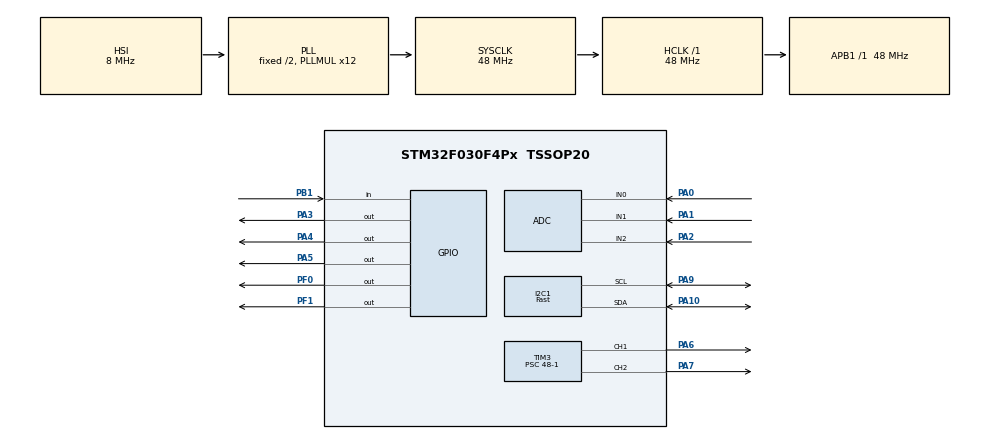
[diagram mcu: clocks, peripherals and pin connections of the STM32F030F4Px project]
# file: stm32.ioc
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ADC.ContinuousConvMode=DISABLE
ADC.DMAContinuousRequests=ENABLE
ADC.EOCSelection=ADC_EOC_SEQ_CONV
ADC.ExternalTrigConv=ADC_EXTERNALTRIGCONV_T1_CC4
ADC.ExternalTrigConvEdge=ADC_EXTERNALTRIGCONVEDGE_FALLING
ADC.SamplingTime=ADC_SAMPLETIME_71CYCLES_5
Dma.ADC.0.Direction=DMA_PERIPH_TO_MEMORY
Dma.ADC.0.Instance=DMA1_Channel1
Dma.ADC.0.MemDataAlignment=DMA_MDATAALIGN_HALFWORD
Dma.ADC.0.MemInc=DMA_MINC_ENABLE
Dma.ADC.0.Mode=DMA_CIRCULAR
Dma.ADC.0.PeriphDataAlignment=DMA_PDATAALIGN_HALFWORD
Dma.ADC.0.PeriphInc=DMA_PINC_DISABLE
Dma.ADC.0.Priority=DMA_PRIORITY_HIGH
Dma.Request0=ADC
I2C1.Analog_Filter=I2C_ANALOGFILTER_ENABLE
I2C1.I2C_Fall_Time=300
I2C1.I2C_Rise_Time=300
I2C1.I2C_Speed_Mode=I2C_Fast
I2C1.OwnAddress=0x58
I2C1.Timing=0x00300208
Mcu.Family=STM32F0
Mcu.Name=STM32F030F4Px
Mcu.Package=TSSOP20
NVIC.DMA1_Channel1_IRQn=true\:1\:0\:true\:false\:true\:false\:true
NVIC.I2C1_IRQn=true\:0\:0\:false\:false\:true\:true\:true
NVIC.TIM14_IRQn=true\:3\:0\:true\:false\:true\:false\:true
NVIC.TimeBase=TIM14_IRQn
NVIC.TimeBaseIP=TIM14
PA0.Mode=IN0
PA0.Signal=ADC_IN0
PA1.Mode=IN1
PA1.Signal=ADC_IN1
PA10.Mode=I2C
PA10.Signal=I2C1_SDA
PA13.Mode=Serial_Wire
PA13.Signal=SYS_SWDIO
PA14.Mode=Serial_Wire
PA14.Signal=SYS_SWCLK
PA2.Mode=IN2
PA2.Signal=ADC_IN2
PA3.GPIO_Speed=GPIO_SPEED_FREQ_MEDIUM
PA3.Signal=GPIO_Output
PA4.GPIO_Speed=GPIO_SPEED_FREQ_MEDIUM
PA4.Signal=GPIO_Output
PA5.Signal=GPIO_Output
PA6.Signal=S_TIM3_CH1
PA7.Signal=S_TIM3_CH2
PA9.Mode=I2C
PA9.Signal=I2C1_SCL
PB1.Signal=GPIO_Input
PF0-OSC_IN.GPIO_Speed=GPIO_SPEED_FREQ_MEDIUM
PF0-OSC_IN.Signal=GPIO_Output
PF1-OSC_OUT.GPIO_Speed=GPIO_SPEED_FREQ_MEDIUM
PF1-OSC_OUT.Signal=GPIO_Output
ProjectManager.HeapSize=0x0
ProjectManager.StackSize=0x400
ProjectManager.TargetToolchain=MDK-ARM V5
RCC.AHBFreq_Value=48000000
RCC.APB1Freq_Value=48000000
RCC.APB1TimFreq_Value=48000000
RCC.HCLKFreq_Value=48000000
RCC.PLLMUL=RCC_PLL_MUL12
RCC.SYSCLKFreq_VALUE=48000000
RCC.SYSCLKSource=RCC_SYSCLKSOURCE_PLLCLK
SH.S_TIM3_CH1.0=TIM3_CH1,PWM Generation1 CH1
SH.S_TIM3_CH2.0=TIM3_CH2,PWM Generation2 CH2
TIM1.AutoReloadPreload=TIM_AUTORELOAD_PRELOAD_ENABLE
TIM1.Channel-PWM\ Generation4\ No\ Output=TIM_CHANNEL_4
TIM1.Period=1000-1
TIM1.Prescaler=48-1
TIM1.Pulse-PWM\ Generation4\ No\ Output=1
TIM1.TIM_MasterOutputTrigger=TIM_TRGO_OC4REF
TIM3.AutoReloadPreload=TIM_AUTORELOAD_PRELOAD_ENABLE
TIM3.Channel-PWM\ Generation1\ CH1=TIM_CHANNEL_1
TIM3.Channel-PWM\ Generation2\ CH2=TIM_CHANNEL_2
TIM3.Period=1000
TIM3.Prescaler=48-1
VP_SYS_VS_tim14.Mode=TIM14
VP_TIM1_VS_no_output4.Mode=PWM Generation4 No Output
board=custom

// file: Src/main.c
/* USER CODE BEGIN Header */
/**
  ******************************************************************************
  * @file           : main.c
  * @brief          : Main program body
  ******************************************************************************
  * @attention
  *
  * <h2><center>&copy; Copyright (c) 2019 STMicroelectronics.
  * All rights reserved.</center></h2>
  *
  * This software component is licensed by ST under BSD 3-Clause license,
  * the "License"; You may not use this file except in compliance with the
  * License. You may obtain a copy of the License at:
  *                        opensource.org/licenses/BSD-3-Clause
  *
  ******************************************************************************
  */
/* USER CODE END Header */

#include "main.h"
#include "user.h"
volatile uint16_t ADC_Raw[3];

ADC_HandleTypeDef hadc;
DMA_HandleTypeDef hdma_adc;

I2C_HandleTypeDef hi2c1;

TIM_HandleTypeDef htim1;
TIM_HandleTypeDef htim3;

void SystemClock_Config(void);
static void MX_GPIO_Init(void);
static void MX_DMA_Init(void);
static void MX_ADC_Init(void);
static void MX_I2C1_Init(void);
static void MX_TIM3_Init(void);
static void MX_TIM1_Init(void);

int main(void)
{

	/* MCU Configuration--------------------------------------------------------*/

	/* Reset of all peripherals, Initializes the Flash interface and the Systick. */
	HAL_Init();

	/* Configure the system clock */
	SystemClock_Config();

	/* Initialize all configured peripherals */
	MX_GPIO_Init();
	MX_DMA_Init();
	MX_ADC_Init();
	MX_I2C1_Init();
	MX_TIM3_Init();
	MX_TIM1_Init();
	/* USER CODE BEGIN 2 */
	__HAL_TIM_SET_AUTORELOAD(&htim3, 1000);
	HAL_TIM_PWM_Start(&htim3, TIM_CHANNEL_1);
	HAL_TIM_PWM_Start(&htim3, TIM_CHANNEL_2);

	// 5k Hz
	__HAL_TIM_SET_AUTORELOAD(&htim1, 200 - 1);

	__HAL_TIM_SET_COMPARE(&htim1, TIM_CHANNEL_4, 1);
	HAL_TIM_OC_Start_IT(&htim1, TIM_CHANNEL_4);
	HAL_ADC_Start_DMA(&hadc, (uint32_t *)ADC_Raw, 3);

	/* USER CODE END 2 */

	/* Infinite loop */
	while (1)
	{
		user_loop();
	}
}

void SystemClock_Config(void)
{
	RCC_OscInitTypeDef RCC_OscInitStruct = {0};
	RCC_ClkInitTypeDef RCC_ClkInitStruct = {0};
	RCC_PeriphCLKInitTypeDef PeriphClkInit = {0};

	/** Initializes the CPU, AHB and APB busses clocks
  */
	RCC_OscInitStruct.OscillatorType = RCC_OSCILLATORTYPE_HSI | RCC_OSCILLATORTYPE_HSI14;
	RCC_OscInitStruct.HSIState = RCC_HSI_ON;
	RCC_OscInitStruct.HSI14State = RCC_HSI14_ON;
	RCC_OscInitStruct.HSICalibrationValue = RCC_HSICALIBRATION_DEFAULT;
	RCC_OscInitStruct.HSI14CalibrationValue = 16;
	RCC_OscInitStruct.PLL.PLLState = RCC_PLL_ON;
	RCC_OscInitStruct.PLL.PLLSource = RCC_PLLSOURCE_HSI;
	RCC_OscInitStruct.PLL.PLLMUL = RCC_PLL_MUL12;
	RCC_OscInitStruct.PLL.PREDIV = RCC_PREDIV_DIV1;
	if (HAL_RCC_OscConfig(&RCC_OscInitStruct) != HAL_OK)
	{
		Error_Handler();
	}
	/** Initializes the CPU, AHB and APB busses clocks
  */
	RCC_ClkInitStruct.ClockType = RCC_CLOCKTYPE_HCLK | RCC_CLOCKTYPE_SYSCLK | RCC_CLOCKTYPE_PCLK1;
	RCC_ClkInitStruct.SYSCLKSource = RCC_SYSCLKSOURCE_PLLCLK;
	RCC_ClkInitStruct.AHBCLKDivider = RCC_SYSCLK_DIV1;
	RCC_ClkInitStruct.APB1CLKDivider = RCC_HCLK_DIV1;

	if (HAL_RCC_ClockConfig(&RCC_ClkInitStruct, FLASH_LATENCY_1) != HAL_OK)
	{
		Error_Handler();
	}
	PeriphClkInit.PeriphClockSelection = RCC_PERIPHCLK_I2C1;
	PeriphClkInit.I2c1ClockSelection = RCC_I2C1CLKSOURCE_HSI;
	if (HAL_RCCEx_PeriphCLKConfig(&PeriphClkInit) != HAL_OK)
	{
		Error_Handler();
	}
}

static void MX_ADC_Init(void)
{

	ADC_ChannelConfTypeDef sConfig = {0};

	/** Configure the global features of the ADC (Clock, Resolution, Data Alignment and number of conversion)
  */
	hadc.Instance = ADC1;
	hadc.Init.ClockPrescaler = ADC_CLOCK_ASYNC_DIV1;
	hadc.Init.Resolution = ADC_RESOLUTION_12B;
	hadc.Init.DataAlign = ADC_DATAALIGN_RIGHT;
	hadc.Init.ScanConvMode = ADC_SCAN_DIRECTION_FORWARD;
	hadc.Init.EOCSelection = ADC_EOC_SEQ_CONV;
	hadc.Init.LowPowerAutoWait = DISABLE;
	hadc.Init.LowPowerAutoPowerOff = DISABLE;
	hadc.Init.ContinuousConvMode = DISABLE;
	hadc.Init.DiscontinuousConvMode = DISABLE;
	hadc.Init.ExternalTrigConv = ADC_EXTERNALTRIGCONV_T1_CC4;
	hadc.Init.ExternalTrigConvEdge = ADC_EXTERNALTRIGCONVEDGE_FALLING;
	hadc.Init.DMAContinuousRequests = ENABLE;
	hadc.Init.Overrun = ADC_OVR_DATA_PRESERVED;
	if (HAL_ADC_Init(&hadc) != HAL_OK)
	{
		Error_Handler();
	}
	/** Configure for the selected ADC regular channel to be converted.
  */
	sConfig.Channel = ADC_CHANNEL_0;
	sConfig.Rank = ADC_RANK_CHANNEL_NUMBER;
	sConfig.SamplingTime = ADC_SAMPLETIME_71CYCLES_5;
	if (HAL_ADC_ConfigChannel(&hadc, &sConfig) != HAL_OK)
	{
		Error_Handler();
	}
	/** Configure for the selected ADC regular channel to be converted.
  */
	sConfig.Channel = ADC_CHANNEL_1;
	if (HAL_ADC_ConfigChannel(&hadc, &sConfig) != HAL_OK)
	{
		Error_Handler();
	}
	/** Configure for the selected ADC regular channel to be converted.
  */
	sConfig.Channel = ADC_CHANNEL_2;
	if (HAL_ADC_ConfigChannel(&hadc, &sConfig) != HAL_OK)
	{
		Error_Handler();
	}
}

static void MX_I2C1_Init(void)
{

	hi2c1.Instance = I2C1;
	hi2c1.Init.Timing = 0x00300208;
	hi2c1.Init.OwnAddress1 = 176;
	hi2c1.Init.AddressingMode = I2C_ADDRESSINGMODE_7BIT;
	hi2c1.Init.DualAddressMode = I2C_DUALADDRESS_DISABLE;
	hi2c1.Init.OwnAddress2 = 0;
	hi2c1.Init.OwnAddress2Masks = I2C_OA2_NOMASK;
	hi2c1.Init.GeneralCallMode = I2C_GENERALCALL_DISABLE;
	hi2c1.Init.NoStretchMode = I2C_NOSTRETCH_DISABLE;
	if (HAL_I2C_Init(&hi2c1) != HAL_OK)
	{
		Error_Handler();
	}
	/** Configure Analogue filter
  */
	if (HAL_I2CEx_ConfigAnalogFilter(&hi2c1, I2C_ANALOGFILTER_ENABLE) != HAL_OK)
	{
		Error_Handler();
	}
	/** Configure Digital filter
  */
	if (HAL_I2CEx_ConfigDigitalFilter(&hi2c1, 0) != HAL_OK)
	{
		Error_Handler();
	}
}

static void MX_TIM1_Init(void)
{

	TIM_MasterConfigTypeDef sMasterConfig = {0};
	TIM_OC_InitTypeDef sConfigOC = {0};
	TIM_BreakDeadTimeConfigTypeDef sBreakDeadTimeConfig = {0};

	htim1.Instance = TIM1;
	htim1.Init.Prescaler = 48 - 1;
	htim1.Init.CounterMode = TIM_COUNTERMODE_UP;
	htim1.Init.Period = 100 - 1;
	htim1.Init.ClockDivision = TIM_CLOCKDIVISION_DIV1;
	htim1.Init.RepetitionCounter = 0;
	htim1.Init.AutoReloadPreload = TIM_AUTORELOAD_PRELOAD_ENABLE;
	if (HAL_TIM_PWM_Init(&htim1) != HAL_OK)
	{
		Error_Handler();
	}
	sMasterConfig.MasterOutputTrigger = TIM_TRGO_OC4REF;
	sMasterConfig.MasterSlaveMode = TIM_MASTERSLAVEMODE_DISABLE;
	if (HAL_TIMEx_MasterConfigSynchronization(&htim1, &sMasterConfig) != HAL_OK)
	{
		Error_Handler();
	}
	sConfigOC.OCMode = TIM_OCMODE_PWM1;
	sConfigOC.Pulse = 1;
	sConfigOC.OCPolarity = TIM_OCPOLARITY_HIGH;
	sConfigOC.OCFastMode = TIM_OCFAST_DISABLE;
	sConfigOC.OCIdleState = TIM_OCIDLESTATE_RESET;
	sConfigOC.OCNIdleState = TIM_OCNIDLESTATE_RESET;
	if (HAL_TIM_PWM_ConfigChannel(&htim1, &sConfigOC, TIM_CHANNEL_4) != HAL_OK)
	{
		Error_Handler();
	}
	sBreakDeadTimeConfig.OffStateRunMode = TIM_OSSR_DISABLE;
	sBreakDeadTimeConfig.OffStateIDLEMode = TIM_OSSI_DISABLE;
	sBreakDeadTimeConfig.LockLevel = TIM_LOCKLEVEL_OFF;
	sBreakDeadTimeConfig.DeadTime = 0;
	sBreakDeadTimeConfig.BreakState = TIM_BREAK_DISABLE;
	sBreakDeadTimeConfig.BreakPolarity = TIM_BREAKPOLARITY_HIGH;
	sBreakDeadTimeConfig.AutomaticOutput = TIM_AUTOMATICOUTPUT_DISABLE;
	if (HAL_TIMEx_ConfigBreakDeadTime(&htim1, &sBreakDeadTimeConfig) != HAL_OK)
	{
		Error_Handler();
	}
}

static void MX_TIM3_Init(void)
{

	TIM_MasterConfigTypeDef sMasterConfig = {0};
	TIM_OC_InitTypeDef sConfigOC = {0};

	htim3.Instance = TIM3;
	htim3.Init.Prescaler = 3 - 1;
	htim3.Init.CounterMode = TIM_COUNTERMODE_UP;
	htim3.Init.Period = 1000;
	htim3.Init.ClockDivision = TIM_CLOCKDIVISION_DIV1;
	htim3.Init.AutoReloadPreload = TIM_AUTORELOAD_PRELOAD_ENABLE;
	if (HAL_TIM_PWM_Init(&htim3) != HAL_OK)
	{
		Error_Handler();
	}
	sMasterConfig.MasterOutputTrigger = TIM_TRGO_RESET;
	sMasterConfig.MasterSlaveMode = TIM_MASTERSLAVEMODE_DISABLE;
	if (HAL_TIMEx_MasterConfigSynchronization(&htim3, &sMasterConfig) != HAL_OK)
	{
		Error_Handler();
	}
	sConfigOC.OCMode = TIM_OCMODE_PWM1;
	sConfigOC.Pulse = 0;
	sConfigOC.OCPolarity = TIM_OCPOLARITY_HIGH;
	sConfigOC.OCFastMode = TIM_OCFAST_DISABLE;
	if (HAL_TIM_PWM_ConfigChannel(&htim3, &sConfigOC, TIM_CHANNEL_1) != HAL_OK)
	{
		Error_Handler();
	}
	if (HAL_TIM_PWM_ConfigChannel(&htim3, &sConfigOC, TIM_CHANNEL_2) != HAL_OK)
	{
		Error_Handler();
	}
	HAL_TIM_MspPostInit(&htim3);
}

static void MX_DMA_Init(void)
{
	/* DMA controller clock enable */
	__HAL_RCC_DMA1_CLK_ENABLE();

	/* DMA interrupt init */
	/* DMA1_Channel1_IRQn interrupt configuration */
	HAL_NVIC_SetPriority(DMA1_Channel1_IRQn, 1, 0);
	HAL_NVIC_EnableIRQ(DMA1_Channel1_IRQn);
}

static void MX_GPIO_Init(void)
{
	GPIO_InitTypeDef GPIO_InitStruct = {0};

	/* GPIO Ports Clock Enable */
	__HAL_RCC_GPIOF_CLK_ENABLE();
	__HAL_RCC_GPIOA_CLK_ENABLE();
	__HAL_RCC_GPIOB_CLK_ENABLE();

	/*Configure GPIO pin Output Level */
	HAL_GPIO_WritePin(GPIOF, GPIO_PIN_0 | GPIO_PIN_1, GPIO_PIN_RESET);

	/*Configure GPIO pin Output Level */
	HAL_GPIO_WritePin(GPIOA, GPIO_PIN_3 | GPIO_PIN_4 | GPIO_PIN_5, GPIO_PIN_RESET);

	/*Configure GPIO pins : PF0 PF1 */
	GPIO_InitStruct.Pin = GPIO_PIN_0 | GPIO_PIN_1;
	GPIO_InitStruct.Mode = GPIO_MODE_OUTPUT_PP;
	GPIO_InitStruct.Pull = GPIO_NOPULL;
	GPIO_InitStruct.Speed = GPIO_SPEED_FREQ_MEDIUM;
	HAL_GPIO_Init(GPIOF, &GPIO_InitStruct);

	/*Configure GPIO pins : PA3 PA4 */
	GPIO_InitStruct.Pin = GPIO_PIN_3 | GPIO_PIN_4;
	GPIO_InitStruct.Mode = GPIO_MODE_OUTPUT_PP;
	GPIO_InitStruct.Pull = GPIO_NOPULL;
	GPIO_InitStruct.Speed = GPIO_SPEED_FREQ_MEDIUM;
	HAL_GPIO_Init(GPIOA, &GPIO_InitStruct);

	/*Configure GPIO pin : PA5 */
	GPIO_InitStruct.Pin = GPIO_PIN_5;
	GPIO_InitStruct.Mode = GPIO_MODE_OUTPUT_PP;
	GPIO_InitStruct.Pull = GPIO_NOPULL;
	GPIO_InitStruct.Speed = GPIO_SPEED_FREQ_LOW;
	HAL_GPIO_Init(GPIOA, &GPIO_InitStruct);

	/*Configure GPIO pin : PB1 */
	GPIO_InitStruct.Pin = GPIO_PIN_1;
	GPIO_InitStruct.Mode = GPIO_MODE_INPUT;
	GPIO_InitStruct.Pull = GPIO_NOPULL;
	HAL_GPIO_Init(GPIOB, &GPIO_InitStruct);
}

void HAL_TIM_PeriodElapsedCallback(TIM_HandleTypeDef *htim)
{
	if (htim->Instance == TIM14)
	{
		HAL_IncTick();
	}
}

void Error_Handler(void)
{
}

/************************ (C) COPYRIGHT STMicroelectronics *****END OF FILE****/
